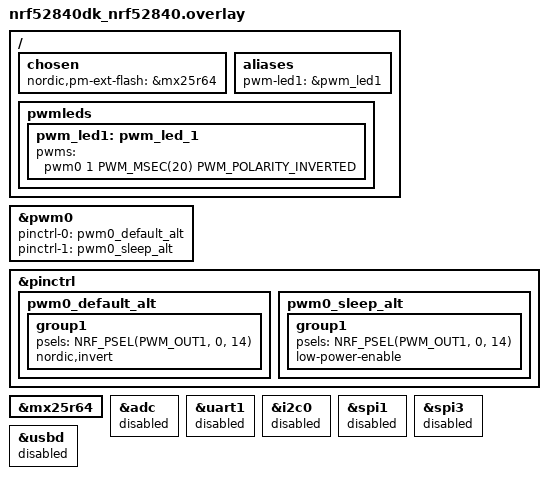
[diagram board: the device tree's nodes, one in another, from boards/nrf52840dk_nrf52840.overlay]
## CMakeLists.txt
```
#
# Copyright (c) 2021 Nordic Semiconductor ASA
#
# SPDX-License-Identifier: LicenseRef-Nordic-5-Clause
#

cmake_minimum_required(VERSION 3.20.0)

find_package(Zephyr HINTS $ENV{ZEPHYR_BASE})

project(matter-light-bulb)

# Enable GNU STD support.
include(${ZEPHYR_CONNECTEDHOMEIP_MODULE_DIR}/config/nrfconnect/app/enable-gnu-std.cmake)

# NORDIC SDK APP START

# Include all source files that are located in the Matter common directory.
include(${ZEPHYR_NRF_MODULE_DIR}/samples/matter/common/cmake/source_common.cmake)

# Include Data Model utils
include(${ZEPHYR_NRF_MODULE_DIR}/samples/matter/common/cmake/data_model.cmake)

include(${ZEPHYR_NRF_MODULE_DIR}/samples/matter/common/cmake/zap_helpers.cmake)
ncs_get_zap_parent_dir(ZAP_PARENT_DIR)

target_include_directories(app PRIVATE
  src
  ${ZAP_PARENT_DIR}
)

target_sources(app PRIVATE
  src/app_task.cpp
  src/main.cpp
  src/zcl_callbacks.cpp
  ${CHIP_ROOT}/src/app/persistence/DeferredAttributePersistenceProvider.cpp
)

ncs_configure_data_model()
# NORDIC SDK APP END
```

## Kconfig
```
#
# Copyright (c) 2022 Nordic Semiconductor
#
# SPDX-License-Identifier: LicenseRef-Nordic-5-Clause
#
mainmenu "Matter nRF Connect Light Bulb Example Application"

# Sample configuration used for Thread networking
if OPENTHREAD

choice OPENTHREAD_NORDIC_LIBRARY_CONFIGURATION
	default OPENTHREAD_NORDIC_LIBRARY_FTD
endchoice

choice OPENTHREAD_DEVICE_TYPE
	default OPENTHREAD_FTD
endchoice

endif # OPENTHREAD

config CHIP_WIFI
	default y if SHIELD_NRF7002EB2

source "$(ZEPHYR_CONNECTEDHOMEIP_MODULE_DIR)/config/nrfconnect/chip-module/Kconfig.features"
source "$(ZEPHYR_CONNECTEDHOMEIP_MODULE_DIR)/config/nrfconnect/chip-module/Kconfig.defaults"
source "$(ZEPHYR_NRF_MODULE_DIR)/samples/matter/common/src/Kconfig"
source "Kconfig.zephyr"
```

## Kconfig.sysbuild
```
#
# Copyright (c) 2023 Nordic Semiconductor ASA
#
# SPDX-License-Identifier: LicenseRef-Nordic-5-Clause
#

#### Radio core selection
config NRF_DEFAULT_IPC_RADIO
	default y

# Enable IEEE802.15.4 serialization to network core
# This config automatically pulls in the `overlay-802154.conf` in the ipc_radio image
config NETCORE_IPC_RADIO_IEEE802154
	default y if SOC_SERIES_NRF53 && !WIFI_NRF70

# Enable Bluetooth serialization to network core
# This config automatically pulls in the `overlay-bt_hci_ipc.conf` in the ipc_radio image
config NETCORE_IPC_RADIO_BT_HCI_IPC
	default y if SOC_SERIES_NRF53

#### Bootloader
choice BOOTLOADER
	default BOOTLOADER_MCUBOOT if !BOARD_NRF21540DK
endchoice

# The nRF54LC10 DK keeps MCUboot but uses a single application slot:
# it has no external flash and its RRAM cannot hold two Matter-sized slots.
# DFU can be added by introducing external flash.
config MATTER_OTA
	default n if BOARD_NRF54LC10DK

if BOOTLOADER_MCUBOOT

#### DFU multi-image support
config DFU_MULTI_IMAGE_PACKAGE_BUILD
	default y

config DFU_MULTI_IMAGE_PACKAGE_APP
	default y

#### DFU network core configuration
if SOC_SERIES_NRF53

choice MCUBOOT_MODE
	default MCUBOOT_MODE_OVERWRITE_ONLY
endchoice

choice BOOT_SIGNATURE_TYPE
	default BOOT_SIGNATURE_TYPE_RSA
endchoice

config SECURE_BOOT_NETCORE
	default y

config NETCORE_APP_UPDATE
	default y

config MCUBOOT_NRF53_MULTI_IMAGE_UPDATE
	default y if NETCORE_APP_UPDATE

config DFU_MULTI_IMAGE_PACKAGE_NET
	default y

endif # SOC_SERIES_NRF53

# Disable Secondary slot for nRF54LC10 DK since it lacks memory to support it.
if BOARD_NRF54LC10DK

choice MCUBOOT_MODE
	default MCUBOOT_MODE_SINGLE_APP
endchoice

endif # BOARD_NRF54LC10DK

endif # BOOTLOADER_MCUBOOT

#### Enable generating factory data
config MATTER_FACTORY_DATA_GENERATE
	default y if !BOARD_NRF21540DK

source "share/sysbuild/Kconfig"
```

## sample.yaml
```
sample:
  description: Matter Light Bulb example
  name: Matter Light Bulb
common:
  tags:
    - sysbuild
    - ci_samples_matter
tests:
  sample.matter.light_bulb.debug:
    sysbuild: true
    build_only: true
    integration_platforms:
      - nrf54lm20dk/nrf54lm20b/cpuapp
    platform_allow:
      - nrf52840dk/nrf52840
      - nrf5340dk/nrf5340/cpuapp
      - nrf54l15dk/nrf54l15/cpuapp
      - nrf54lm20dk/nrf54lm20b/cpuapp
      - nrf54lm20dk/nrf54lm20a/cpuapp
  sample.matter.light_bulb.nrf7002eb2.debug:
    sysbuild: true
    build_only: true
    extra_args:
      - light_bulb_SHIELD=nrf7002eb2
      - SB_CONFIG_WIFI_NRF70=y
    integration_platforms:
      - nrf54lm20dk/nrf54lm20b/cpuapp
      - nrf54lm20dk/nrf54lm20a/cpuapp
    platform_allow:
      - nrf54lm20dk/nrf54lm20b/cpuapp
      - nrf54lm20dk/nrf54lm20a/cpuapp
  sample.matter.light_bulb.release:
    sysbuild: true
    build_only: true
    extra_args:
      - FILE_SUFFIX=release
    integration_platforms:
      - nrf54lm20dk/nrf54lm20b/cpuapp
      - nrf54lm20dk/nrf54lm20a/cpuapp
    platform_allow:
      - nrf52840dk/nrf52840
      - nrf5340dk/nrf5340/cpuapp
      - nrf54l15dk/nrf54l15/cpuapp
      - nrf54lm20dk/nrf54lm20b/cpuapp
      - nrf54lm20dk/nrf54lm20a/cpuapp
  sample.matter.light_bulb.nrf7002eb2.release:
    sysbuild: true
    build_only: true
    extra_args:
      - FILE_SUFFIX=release
      - light_bulb_SHIELD=nrf7002eb2
      - SB_CONFIG_WIFI_NRF70=y
    integration_platforms:
      - nrf54lm20dk/nrf54lm20b/cpuapp
      - nrf54lm20dk/nrf54lm20a/cpuapp
    platform_allow:
      - nrf54lm20dk/nrf54lm20b/cpuapp
      - nrf54lm20dk/nrf54lm20a/cpuapp
  sample.matter.light_bulb.ffs:
    sysbuild: true
    build_only: true
    extra_args:
      - CONFIG_CHIP_COMMISSIONABLE_DEVICE_TYPE=y
      - CONFIG_CHIP_ROTATING_DEVICE_ID=y
      - CONFIG_CHIP_DEVICE_TYPE=257
    integration_platforms:
      - nrf52840dk/nrf52840
      - nrf54l15dk/nrf54l15/cpuapp
      - nrf54lm20dk/nrf54lm20b/cpuapp
      - nrf54lm20dk/nrf54lm20a/cpuapp
    platform_allow:
      - nrf52840dk/nrf52840
      - nrf5340dk/nrf5340/cpuapp
      - nrf54l15dk/nrf54l15/cpuapp
      - nrf54lm20dk/nrf54lm20b/cpuapp
      - nrf54lm20dk/nrf54lm20a/cpuapp
      - nrf54lc10dk/nrf54lc10a/cpuapp
  sample.matter.light_bulb.nrf7002eb2.ffs:
    sysbuild: true
    build_only: true
    extra_args:
      - CONFIG_CHIP_COMMISSIONABLE_DEVICE_TYPE=y
      - CONFIG_CHIP_ROTATING_DEVICE_ID=y
      - CONFIG_CHIP_DEVICE_TYPE=257
      - light_bulb_SHIELD=nrf7002eb2
      - SB_CONFIG_WIFI_NRF70=y
    integration_platforms:
      - nrf54lm20dk/nrf54lm20b/cpuapp
      - nrf54lm20dk/nrf54lm20a/cpuapp
    platform_allow:
      - nrf54lm20dk/nrf54lm20b/cpuapp
      - nrf54lm20dk/nrf54lm20a/cpuapp
  sample.matter.light_bulb.debug.nrf21540ek:
    sysbuild: true
    build_only: true
    extra_args:
      - light_bulb_SHIELD=nrf21540ek
    integration_platforms:
      - nrf52840dk/nrf52840
    platform_allow: nrf52840dk/nrf52840
  sample.matter.light_bulb.debug.nrf21540ek_fwd:
    sysbuild: true
    build_only: true
    extra_args:
      - light_bulb_SHIELD=nrf21540ek
      - ipc_radio_SHIELD=nrf21540ek
    integration_platforms:
      - nrf5340dk/nrf5340/cpuapp
    platform_allow: nrf5340dk/nrf5340/cpuapp
  # Sample to execute load tests
  sample.matter.light_bulb.memory_profiling:
    sysbuild: true
    build_only: true
    extra_args:
      - CONFIG_CHIP_MEMORY_PROFILING=y
      - CONFIG_SHELL_MINIMAL=y
      - CONFIG_CHIP_FACTORY_RESET_TIME_MEASUREMENT=y
    platform_allow:
      - nrf52840dk/nrf52840
      - nrf5340dk/nrf5340/cpuapp
      - nrf54l15dk/nrf54l15/cpuapp
      - nrf54lm20dk/nrf54lm20b/cpuapp
      - nrf54lm20dk/nrf54lm20a/cpuapp
      - nrf54lc10dk/nrf54lc10a/cpuapp
    integration_platforms:
      - nrf54l15dk/nrf54l15/cpuapp
      - nrf54lm20dk/nrf54lm20b/cpuapp
      - nrf54lm20dk/nrf54lm20a/cpuapp
  sample.matter.light_bulb.nrf7002eb2.memory_profiling:
    sysbuild: true
    build_only: true
    extra_args:
      - CONFIG_CHIP_MEMORY_PROFILING=y
      - CONFIG_SHELL_MINIMAL=y
      - CONFIG_CHIP_FACTORY_RESET_TIME_MEASUREMENT=y
      - light_bulb_SHIELD=nrf7002eb2
      - SB_CONFIG_WIFI_NRF70=y
    platform_allow:
      - nrf54lm20dk/nrf54lm20b/cpuapp
      - nrf54lm20dk/nrf54lm20a/cpuapp
    integration_platforms:
      - nrf54lm20dk/nrf54lm20b/cpuapp
      - nrf54lm20dk/nrf54lm20a/cpuapp
  sample.matter.light_bulb.tfm:
    sysbuild: true
    build_only: true
    extra_args:
      - FILE_SUFFIX=tfm
    integration_platforms:
      - nrf54l15dk/nrf54l15/cpuapp/ns
    platform_allow:
      - nrf54l15dk/nrf54l15/cpuapp/ns
```

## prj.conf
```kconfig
#
# Copyright (c) 2022 Nordic Semiconductor ASA
#
# SPDX-License-Identifier: LicenseRef-Nordic-5-Clause
#

# Enable CHIP
CONFIG_CHIP=y
CONFIG_CHIP_PROJECT_CONFIG="src/chip_project_config.h"
CONFIG_CHIP_DEVICE_PRODUCT_NAME="Matter Light Bulb"

# Configure ZAP file name
CONFIG_NCS_SAMPLE_MATTER_ZAP_FILE_PATH="${APPLICATION_CONFIG_DIR}/src/default_zap/light_bulb.zap"

# 32773 == 0x8005 (example lighting-app)
CONFIG_CHIP_DEVICE_PRODUCT_ID=32773
CONFIG_STD_CPP17=y

# Enable Matter pairing automatically on application start.
CONFIG_CHIP_ENABLE_PAIRING_AUTOSTART=y

# Enable Matter extended announcement and increase duration to 1 hour.
CONFIG_CHIP_BLE_EXT_ADVERTISING=y
CONFIG_CHIP_BLE_ADVERTISING_DURATION=60

# Add support for LEDs and buttons on Nordic development kits
CONFIG_DK_LIBRARY=y
CONFIG_PWM=y

# Bluetooth Low Energy configuration
CONFIG_BT_DEVICE_NAME="MatterLight"

# Other settings
CONFIG_THREAD_NAME=y
CONFIG_MPU_STACK_GUARD=y
CONFIG_RESET_ON_FATAL_ERROR=n
CONFIG_CHIP_LIB_SHELL=y
CONFIG_NCS_SAMPLE_MATTER_TEST_SHELL=y

# Reduce application size
CONFIG_USE_SEGGER_RTT=n
```

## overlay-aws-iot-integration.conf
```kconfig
#
# Copyright (c) 2023 Nordic Semiconductor ASA
#
# SPDX-License-Identifier: LicenseRef-Nordic-5-Clause
#

# Enable matter integration layer
CONFIG_AWS_IOT_INTEGRATION=y
CONFIG_AWS_IOT_INTEGRATION_LOG_LEVEL_DBG=y

# AWS IoT library
CONFIG_AWS_IOT=y
CONFIG_AWS_IOT_BROKER_HOST_NAME="xxx.amazonaws.com"
CONFIG_AWS_IOT_CLIENT_ID_STATIC="my-thing"
CONFIG_AWS_IOT_AUTO_DEVICE_SHADOW_REQUEST=n
CONFIG_AWS_IOT_TOPIC_UPDATE_DELTA_SUBSCRIBE=y

# JSON
CONFIG_JSON_LIBRARY=y

# MQTT helper library
CONFIG_MQTT_HELPER_PROVISION_CERTIFICATES=y
CONFIG_MQTT_HELPER_CERTIFICATES_FOLDER="src/aws_iot_integration/certs"
CONFIG_MQTT_HELPER_SEC_TAG=201

# MQTT - Maximum MQTT keepalive timeout specified by AWS IoT Core
CONFIG_MQTT_KEEPALIVE=1200
CONFIG_MQTT_CLEAN_SESSION=y

# MBed TLS
CONFIG_MBEDTLS_HEAP_SIZE=98304
CONFIG_MBEDTLS_RSA_C=y
CONFIG_PSA_WANT_ALG_SHA_384=y
CONFIG_MBEDTLS_SSL_OUT_CONTENT_LEN=1024

# PSA
CONFIG_PSA_WANT_KEY_TYPE_RSA_PUBLIC_KEY=y
CONFIG_PSA_WANT_RSA_KEY_SIZE_2048=y

# Zephyr Networking
CONFIG_NET_CONNECTION_MANAGER=y
CONFIG_NET_DHCPV4=y
CONFIG_NET_IPV4=y
CONFIG_NET_TCP=y
CONFIG_NET_SOCKETS_SOCKOPT_TLS=y
CONFIG_NET_MAX_CONN=8

# Required events at least 9 ZVFS events:
# 5 x WPA supplicant
# 1 x Socket Service
# 1 x DNS resolver
# 1 x Matter Stack
# 1 x MQTT / AWS IoT integration
CONFIG_ZVFS_EVENTFD_MAX=10
CONFIG_ZVFS_POLL_MAX=12
CONFIG_DNS_RESOLVER=y

# Adjust NET configurations to reduce the likelyhood of congestion in the TCP stack when there are
# multiple NET users in the system.
CONFIG_NET_PKT_RX_COUNT=14
CONFIG_NET_PKT_TX_COUNT=14
CONFIG_NET_BUF_RX_COUNT=54
CONFIG_NET_BUF_TX_COUNT=54
CONFIG_NET_TCP_MAX_SEND_WINDOW_SIZE=1024

# Free some memory
CONFIG_SHELL=n
CONFIG_CHIP_LIB_SHELL=n
CONFIG_ASSERT=n
CONFIG_LTO=y
CONFIG_ISR_TABLES_LOCAL_DECLARATION=y
```

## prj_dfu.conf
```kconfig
#
# Copyright (c) 2021 Nordic Semiconductor ASA
#
# SPDX-License-Identifier: LicenseRef-Nordic-5-Clause
#

# Enable CHIP
CONFIG_CHIP=y
CONFIG_CHIP_PROJECT_CONFIG="src/chip_project_config.h"
CONFIG_STD_CPP14=y

# Enable CHIP pairing automatically on application start.
CONFIG_CHIP_ENABLE_PAIRING_AUTOSTART=y

# General networking settings
CONFIG_NETWORKING=y
CONFIG_NET_IPV6_NBR_CACHE=n
CONFIG_NET_IPV6_MLD=n
CONFIG_NET_SOCKETS_POLL_MAX=5

# Enable OpenThread MTD
CONFIG_NET_L2_OPENTHREAD=y

CONFIG_OPENTHREAD_MTD=y
CONFIG_OPENTHREAD_FTD=n
CONFIG_OPENTHREAD_SLAAC=y
CONFIG_OPENTHREAD_MTD_NETDIAG=y
CONFIG_OPENTHREAD_MANUAL_START=y
CONFIG_OPENTHREAD_THREAD_STACK_SIZE=6144
CONFIG_OPENTHREAD_NUM_MESSAGE_BUFFERS=64

CONFIG_OPENTHREAD_PANID=4660
CONFIG_OPENTHREAD_CHANNEL=15
CONFIG_OPENTHREAD_NETWORK_NAME="OpenThread"
CONFIG_OPENTHREAD_XPANID="11:11:11:11:22:22:22:22"

# Enable Bluetooth Low Energy
CONFIG_BT=y
CONFIG_BT_PERIPHERAL=y
CONFIG_BT_PERIPHERAL_PREF_MIN_INT=12
CONFIG_BT_PERIPHERAL_PREF_MAX_INT=12
CONFIG_BT_GAP_AUTO_UPDATE_CONN_PARAMS=y
CONFIG_BT_GATT_DYNAMIC_DB=y
CONFIG_BT_DEVICE_APPEARANCE=0
CONFIG_BT_DEVICE_NAME_DYNAMIC=y
CONFIG_BT_DEVICE_NAME_MAX=15
CONFIG_BT_DEVICE_NAME="MatterLight"
CONFIG_BT_MAX_CONN=1
CONFIG_BT_SMP=y
CONFIG_BT_PRIVACY=y
CONFIG_BT_MAX_PAIRED=0
CONFIG_BT_BONDABLE=n
CONFIG_BT_TINYCRYPT_ECC=n
CONFIG_BT_SMP_OOB_LEGACY_PAIR_ONLY=y

# Use NFC to share commissioning information
CONFIG_CHIP_NFC_COMMISSIONING=y

# Use nrf_security
CONFIG_OPENTHREAD_NRF_SECURITY_CHOICE=y

CONFIG_CC3XX_BACKEND=y
CONFIG_OBERON_BACKEND=y

CONFIG_MBEDTLS_ENABLE_HEAP=y
CONFIG_MBEDTLS_HEAP_SIZE=15360
CONFIG_MBEDTLS_TLS_LIBRARY=y
CONFIG_NRF_SECURITY_ADVANCED=y

CONFIG_MBEDTLS_AES_C=y
CONFIG_MBEDTLS_ECP_C=y
CONFIG_MBEDTLS_ECP_DP_SECP256R1_ENABLED=y
CONFIG_MBEDTLS_CTR_DRBG_C=y
CONFIG_MBEDTLS_CIPHER_MODE_CTR=y
CONFIG_MBEDTLS_ECJPAKE_C=y
CONFIG_MBEDTLS_SHA256_C=y
CONFIG_MBEDTLS_PK_C=y
CONFIG_MBEDTLS_PK_WRITE_C=y
CONFIG_MBEDTLS_X509_CREATE_C=y
CONFIG_MBEDTLS_X509_CSR_WRITE_C=y

# Use SHA256 implementation from Oberon
CONFIG_CHOICE_OBERON_MBEDTLS_SHA256_C=y

# Disable unneeded crypto operations
CONFIG_MBEDTLS_SHA512_C=n
CONFIG_MBEDTLS_CIPHER_MODE_XTS=n
CONFIG_MBEDTLS_CHACHA20_C=n
CONFIG_MBEDTLS_POLY1305_C=n
CONFIG_MBEDTLS_CHACHAPOLY_C=n
CONFIG_MBEDTLS_GCM_C=n
CONFIG_MBEDTLS_RSA_C=n
CONFIG_OBERON_MBEDTLS_AES_C=n

# Add support for LEDs and buttons on Nordic development kits
CONFIG_DK_LIBRARY=y
CONFIG_PWM=y

# Other settings
CONFIG_LOG=y
CONFIG_LOG_MODE_MINIMAL=y
CONFIG_PRINTK_SYNC=y
CONFIG_MAIN_STACK_SIZE=8192
CONFIG_INIT_STACKS=y
CONFIG_HW_STACK_PROTECTION=y
CONFIG_THREAD_NAME=y
CONFIG_SHELL=y

# Enable bootloader and DFU related configs
CONFIG_BOOTLOADER_MCUBOOT=y

# QSPI configuration
CONFIG_NORDIC_QSPI_NOR=y
CONFIG_NORDIC_QSPI_NOR_FLASH_LAYOUT_PAGE_SIZE=4096
CONFIG_NORDIC_QSPI_NOR_STACK_WRITE_BUFFER_SIZE=16

# External flash memory configuration
CONFIG_PM_EXTERNAL_FLASH_SUPPORT_LEGACY=y
CONFIG_PM_EXTERNAL_FLASH=y
CONFIG_PM_EXTERNAL_FLASH_DEV_NAME="MX25R64"
CONFIG_PM_EXTERNAL_FLASH_SIZE=0x800000
CONFIG_PM_EXTERNAL_FLASH_BASE=0

# MCU Manager and SMP configuration
CONFIG_MCUMGR=y
CONFIG_MCUMGR_CMD_IMG_MGMT=y
CONFIG_MCUMGR_CMD_OS_MGMT=y
CONFIG_MCUMGR_SMP_BT=y
CONFIG_MCUMGR_SMP_BT_AUTHEN=n
CONFIG_MCUMGR_BUF_COUNT=6

# Increase BT MTU and RX buffer for big size DFU messages
CONFIG_BT_L2CAP_TX_MTU=260
CONFIG_BT_BUF_ACL_RX_SIZE=264

# Increase system workqueue size, as SMP is processed within it
CONFIG_SYSTEM_WORKQUEUE_STACK_SIZE=2800
```

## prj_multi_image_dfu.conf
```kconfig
#
# Copyright (c) 2021 Nordic Semiconductor ASA
#
# SPDX-License-Identifier: LicenseRef-Nordic-5-Clause
#

# Enable CHIP
CONFIG_CHIP=y
CONFIG_CHIP_PROJECT_CONFIG="src/chip_project_config.h"
CONFIG_STD_CPP14=y

# Enable CHIP pairing automatically on application start.
CONFIG_CHIP_ENABLE_PAIRING_AUTOSTART=y

# General networking settings
CONFIG_NETWORKING=y
CONFIG_NET_IPV6_NBR_CACHE=n
CONFIG_NET_IPV6_MLD=n
CONFIG_NET_SOCKETS_POLL_MAX=5

# Enable OpenThread MTD
CONFIG_NET_L2_OPENTHREAD=y

CONFIG_OPENTHREAD_MTD=y
CONFIG_OPENTHREAD_FTD=n
CONFIG_OPENTHREAD_SLAAC=y
CONFIG_OPENTHREAD_MTD_NETDIAG=y
CONFIG_OPENTHREAD_MANUAL_START=y
CONFIG_OPENTHREAD_THREAD_STACK_SIZE=6144
CONFIG_OPENTHREAD_NUM_MESSAGE_BUFFERS=64

CONFIG_OPENTHREAD_PANID=4660
CONFIG_OPENTHREAD_CHANNEL=15
CONFIG_OPENTHREAD_NETWORK_NAME="OpenThread"
CONFIG_OPENTHREAD_XPANID="11:11:11:11:22:22:22:22"

# Enable Thread 1.2 features
CONFIG_OPENTHREAD_THREAD_VERSION_1_2=y
CONFIG_OPENTHREAD_DUA=y
CONFIG_OPENTHREAD_MLR=y

# Enable Bluetooth Low Energy
CONFIG_BT=y
CONFIG_BT_PERIPHERAL=y
CONFIG_BT_PERIPHERAL_PREF_MIN_INT=12
CONFIG_BT_PERIPHERAL_PREF_MAX_INT=12
CONFIG_BT_GAP_AUTO_UPDATE_CONN_PARAMS=y
CONFIG_BT_GATT_DYNAMIC_DB=y
CONFIG_BT_DEVICE_APPEARANCE=0
CONFIG_BT_DEVICE_NAME_DYNAMIC=y
CONFIG_BT_DEVICE_NAME_MAX=15
CONFIG_BT_DEVICE_NAME="MatterLight"
CONFIG_BT_MAX_CONN=1

# Use NFC to share commissioning information
CONFIG_CHIP_NFC_COMMISSIONING=y

# Use nrf_security
CONFIG_OPENTHREAD_NRF_SECURITY_CHOICE=y

CONFIG_CC3XX_BACKEND=n
CONFIG_OBERON_BACKEND=y

CONFIG_MBEDTLS_ENABLE_HEAP=y
CONFIG_MBEDTLS_HEAP_SIZE=15360
CONFIG_MBEDTLS_TLS_LIBRARY=y
CONFIG_NRF_SECURITY_ADVANCED=y

CONFIG_MBEDTLS_AES_C=y
CONFIG_MBEDTLS_ECP_C=y
CONFIG_MBEDTLS_ECP_DP_SECP256R1_ENABLED=y
CONFIG_MBEDTLS_CTR_DRBG_C=y
CONFIG_MBEDTLS_CIPHER_MODE_CTR=y
CONFIG_MBEDTLS_ECJPAKE_C=y
CONFIG_MBEDTLS_SHA256_C=y
CONFIG_MBEDTLS_PK_C=y
CONFIG_MBEDTLS_PK_WRITE_C=y
CONFIG_MBEDTLS_X509_CREATE_C=y
CONFIG_MBEDTLS_X509_CSR_WRITE_C=y
# Disable unneeded crypto operations
CONFIG_MBEDTLS_SHA384_C=n
CONFIG_MBEDTLS_SHA512_C=n
CONFIG_MBEDTLS_CIPHER_MODE_XTS=n
CONFIG_MBEDTLS_CHACHA20_C=n
CONFIG_MBEDTLS_POLY1305_C=n
CONFIG_MBEDTLS_CHACHAPOLY_C=n
CONFIG_MBEDTLS_GCM_C=n
CONFIG_MBEDTLS_RSA_C=n

# Add support for LEDs and buttons on Nordic development kits
CONFIG_DK_LIBRARY=y
CONFIG_PWM=y

# Other settings
CONFIG_LOG=y
CONFIG_LOG_MODE_MINIMAL=y
CONFIG_MATTER_LOG_LEVEL_DBG=y
CONFIG_PRINTK_SYNC=y
CONFIG_MAIN_STACK_SIZE=8192
CONFIG_INIT_STACKS=y
CONFIG_HW_STACK_PROTECTION=y
CONFIG_HWINFO=y
CONFIG_THREAD_NAME=y
CONFIG_SHELL=y
CONFIG_ASSERT=y

# Enable bootloader and DFU related configs
CONFIG_BOOTLOADER_MCUBOOT=y
CONFIG_UPDATEABLE_IMAGE_NUMBER=2

# QSPI configuration
CONFIG_NORDIC_QSPI_NOR=y
CONFIG_NORDIC_QSPI_NOR_FLASH_LAYOUT_PAGE_SIZE=4096
CONFIG_NORDIC_QSPI_NOR_STACK_WRITE_BUFFER_SIZE=16

# MCU Manager and SMP configuration
CONFIG_MCUMGR=y
CONFIG_MCUMGR_CMD_IMG_MGMT=y
CONFIG_MCUMGR_CMD_OS_MGMT=y
CONFIG_MCUMGR_SMP_BT=y
CONFIG_MCUMGR_SMP_BT_AUTHEN=n
CONFIG_MCUMGR_BUF_COUNT=6

# Increase BT MTU and RX buffer for big size DFU messages
CONFIG_BT_L2CAP_TX_MTU=498
CONFIG_BT_BUF_ACL_TX_SIZE=251
CONFIG_BT_BUF_ACL_RX_SIZE=502

# Increase max number of pending GATT notification callbacks
CONFIG_BT_CONN_TX_MAX=6

# Increase system workqueue size, as SMP is processed within it
CONFIG_SYSTEM_WORKQUEUE_STACK_SIZE=2800

# FLASH nop device is enabled to prevent bus faults when mcumgr tries to access
# simulated partition with network core image data.
CONFIG_FLASH_NOP_DEVICE=y

# Enable custom SMP request to erase settings partition.
CONFIG_MCUMGR_GRP_ZEPHYR_BASIC=y
CONFIG_MCUMGR_GRP_BASIC_CMD_STORAGE_ERASE=y
```

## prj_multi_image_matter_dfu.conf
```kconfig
#
# Copyright (c) 2022 Nordic Semiconductor ASA
#
# SPDX-License-Identifier: LicenseRef-Nordic-5-Clause
#

# Enable CHIP
CONFIG_CHIP=y
CONFIG_CHIP_PROJECT_CONFIG="src/chip_project_config.h"
CONFIG_STD_CPP14=y

# Enable CHIP pairing automatically on application start.
CONFIG_CHIP_ENABLE_PAIRING_AUTOSTART=y

# General networking settings
CONFIG_NETWORKING=y
CONFIG_NET_IPV6_NBR_CACHE=n
CONFIG_NET_IPV6_MLD=n
CONFIG_NET_SOCKETS_POLL_MAX=5

# Enable OpenThread MTD
CONFIG_NET_L2_OPENTHREAD=y

CONFIG_OPENTHREAD_MTD=y
CONFIG_OPENTHREAD_FTD=n
CONFIG_OPENTHREAD_SLAAC=y
CONFIG_OPENTHREAD_MTD_NETDIAG=y
CONFIG_OPENTHREAD_MANUAL_START=y
CONFIG_OPENTHREAD_NUM_MESSAGE_BUFFERS=64

CONFIG_OPENTHREAD_PANID=4660
CONFIG_OPENTHREAD_CHANNEL=15
CONFIG_OPENTHREAD_NETWORK_NAME="OpenThread"
CONFIG_OPENTHREAD_XPANID="11:11:11:11:22:22:22:22"

# Enable Thread 1.2 features
CONFIG_OPENTHREAD_THREAD_VERSION_1_2=y
CONFIG_OPENTHREAD_DUA=y
CONFIG_OPENTHREAD_MLR=y

# Enable Bluetooth Low Energy
CONFIG_BT=y
CONFIG_BT_PERIPHERAL=y
CONFIG_BT_PERIPHERAL_PREF_MIN_INT=36
CONFIG_BT_PERIPHERAL_PREF_MAX_INT=36
CONFIG_BT_GAP_AUTO_UPDATE_CONN_PARAMS=y
CONFIG_BT_GATT_DYNAMIC_DB=y
CONFIG_BT_DEVICE_APPEARANCE=0
CONFIG_BT_DEVICE_NAME_DYNAMIC=y
CONFIG_BT_DEVICE_NAME_MAX=15
CONFIG_BT_DEVICE_NAME="MatterLight"
CONFIG_BT_MAX_CONN=1
CONFIG_BT_L2CAP_TX_MTU=247
CONFIG_BT_BUF_ACL_RX_SIZE=251
CONFIG_BT_BUF_ACL_TX_SIZE=251
CONFIG_BT_RX_STACK_SIZE=1120

# Use NFC to share commissioning information
CONFIG_CHIP_NFC_COMMISSIONING=y

# Use nrf_security
CONFIG_OPENTHREAD_NRF_SECURITY_CHOICE=y

CONFIG_CC3XX_BACKEND=n
CONFIG_OBERON_BACKEND=y

CONFIG_MBEDTLS_ENABLE_HEAP=y
CONFIG_MBEDTLS_HEAP_SIZE=15360
CONFIG_MBEDTLS_TLS_LIBRARY=y
CONFIG_NRF_SECURITY_ADVANCED=y

CONFIG_MBEDTLS_AES_C=y
CONFIG_MBEDTLS_ECP_C=y
CONFIG_MBEDTLS_ECP_DP_SECP256R1_ENABLED=y
CONFIG_MBEDTLS_CTR_DRBG_C=y
CONFIG_MBEDTLS_CIPHER_MODE_CTR=y
CONFIG_MBEDTLS_ECJPAKE_C=y
CONFIG_MBEDTLS_SHA256_C=y
CONFIG_MBEDTLS_PK_C=y
CONFIG_MBEDTLS_PK_WRITE_C=y
CONFIG_MBEDTLS_X509_CREATE_C=y
CONFIG_MBEDTLS_X509_CSR_WRITE_C=y

# Disable unneeded crypto operations
CONFIG_MBEDTLS_SHA384_C=n
CONFIG_MBEDTLS_SHA512_C=n
CONFIG_MBEDTLS_CIPHER_MODE_XTS=n
CONFIG_MBEDTLS_CHACHA20_C=n
CONFIG_MBEDTLS_POLY1305_C=n
CONFIG_MBEDTLS_CHACHAPOLY_C=n
CONFIG_MBEDTLS_GCM_C=n
CONFIG_MBEDTLS_RSA_C=n

# Add support for LEDs and buttons on Nordic development kits
CONFIG_DK_LIBRARY=y
CONFIG_PWM=y

# Other settings
CONFIG_LOG=y
CONFIG_LOG_MODE_MINIMAL=y
CONFIG_MATTER_LOG_LEVEL_DBG=y
CONFIG_PRINTK_SYNC=y
CONFIG_MAIN_STACK_SIZE=8192
CONFIG_INIT_STACKS=y
CONFIG_HW_STACK_PROTECTION=y
CONFIG_FPU=y
CONFIG_HWINFO=y
CONFIG_THREAD_NAME=y
CONFIG_SHELL=y
CONFIG_ASSERT=y

# Enable bootloader and DFU related configs
CONFIG_BOOTLOADER_MCUBOOT=y
CONFIG_UPDATEABLE_IMAGE_NUMBER=2

# QSPI configuration
CONFIG_NORDIC_QSPI_NOR=y
CONFIG_NORDIC_QSPI_NOR_FLASH_LAYOUT_PAGE_SIZE=4096
CONFIG_NORDIC_QSPI_NOR_STACK_WRITE_BUFFER_SIZE=16

# FLASH nop device is needed to access network core image data.
CONFIG_FLASH_NOP_DEVICE=y

# Enable Matter OTA
CONFIG_CHIP_OTA_REQUESTOR=y
CONFIG_IMG_MANAGER=y
```

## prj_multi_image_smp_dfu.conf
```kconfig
#
# Copyright (c) 2021 Nordic Semiconductor ASA
#
# SPDX-License-Identifier: LicenseRef-Nordic-5-Clause
#

# Enable CHIP
CONFIG_CHIP=y
CONFIG_CHIP_PROJECT_CONFIG="src/chip_project_config.h"
CONFIG_STD_CPP14=y

# Enable CHIP pairing automatically on application start.
CONFIG_CHIP_ENABLE_PAIRING_AUTOSTART=y

# General networking settings
CONFIG_NETWORKING=y
CONFIG_NET_IPV6_NBR_CACHE=n
CONFIG_NET_IPV6_MLD=n
CONFIG_NET_SOCKETS_POLL_MAX=5

# Enable OpenThread MTD
CONFIG_NET_L2_OPENTHREAD=y

CONFIG_OPENTHREAD_MTD=y
CONFIG_OPENTHREAD_FTD=n
CONFIG_OPENTHREAD_SLAAC=y
CONFIG_OPENTHREAD_MTD_NETDIAG=y
CONFIG_OPENTHREAD_MANUAL_START=y
CONFIG_OPENTHREAD_NUM_MESSAGE_BUFFERS=64

CONFIG_OPENTHREAD_PANID=4660
CONFIG_OPENTHREAD_CHANNEL=15
CONFIG_OPENTHREAD_NETWORK_NAME="OpenThread"
CONFIG_OPENTHREAD_XPANID="11:11:11:11:22:22:22:22"

# Enable Thread 1.2 features
CONFIG_OPENTHREAD_THREAD_VERSION_1_2=y
CONFIG_OPENTHREAD_DUA=y
CONFIG_OPENTHREAD_MLR=y

# Enable Bluetooth Low Energy
CONFIG_BT=y
CONFIG_BT_PERIPHERAL=y
CONFIG_BT_PERIPHERAL_PREF_MIN_INT=36
CONFIG_BT_PERIPHERAL_PREF_MAX_INT=36
CONFIG_BT_GAP_AUTO_UPDATE_CONN_PARAMS=y
CONFIG_BT_GATT_DYNAMIC_DB=y
CONFIG_BT_DEVICE_APPEARANCE=0
CONFIG_BT_DEVICE_NAME_DYNAMIC=y
CONFIG_BT_DEVICE_NAME_MAX=15
CONFIG_BT_DEVICE_NAME="MatterLight"
CONFIG_BT_MAX_CONN=1
CONFIG_BT_RX_STACK_SIZE=1120

# Use NFC to share commissioning information
CONFIG_CHIP_NFC_COMMISSIONING=y

# Use nrf_security
CONFIG_OPENTHREAD_NRF_SECURITY_CHOICE=y

CONFIG_CC3XX_BACKEND=n
CONFIG_OBERON_BACKEND=y

CONFIG_MBEDTLS_ENABLE_HEAP=y
CONFIG_MBEDTLS_HEAP_SIZE=15360
CONFIG_MBEDTLS_TLS_LIBRARY=y
CONFIG_NRF_SECURITY_ADVANCED=y

CONFIG_MBEDTLS_AES_C=y
CONFIG_MBEDTLS_ECP_C=y
CONFIG_MBEDTLS_ECP_DP_SECP256R1_ENABLED=y
CONFIG_MBEDTLS_CTR_DRBG_C=y
CONFIG_MBEDTLS_CIPHER_MODE_CTR=y
CONFIG_MBEDTLS_ECJPAKE_C=y
CONFIG_MBEDTLS_SHA256_C=y
CONFIG_MBEDTLS_PK_C=y
CONFIG_MBEDTLS_PK_WRITE_C=y
CONFIG_MBEDTLS_X509_CREATE_C=y
CONFIG_MBEDTLS_X509_CSR_WRITE_C=y

# Disable unneeded crypto operations
CONFIG_MBEDTLS_SHA384_C=n
CONFIG_MBEDTLS_SHA512_C=n
CONFIG_MBEDTLS_CIPHER_MODE_XTS=n
CONFIG_MBEDTLS_CHACHA20_C=n
CONFIG_MBEDTLS_POLY1305_C=n
CONFIG_MBEDTLS_CHACHAPOLY_C=n
CONFIG_MBEDTLS_GCM_C=n
CONFIG_MBEDTLS_RSA_C=n

# Add support for LEDs and buttons on Nordic development kits
CONFIG_DK_LIBRARY=y
CONFIG_PWM=y

# Other settings
CONFIG_LOG=y
CONFIG_LOG_MODE_MINIMAL=y
CONFIG_MATTER_LOG_LEVEL_DBG=y
CONFIG_PRINTK_SYNC=y
CONFIG_MAIN_STACK_SIZE=8192
CONFIG_INIT_STACKS=y
CONFIG_HW_STACK_PROTECTION=y
CONFIG_FPU=y
CONFIG_HWINFO=y
CONFIG_THREAD_NAME=y
CONFIG_SHELL=y
CONFIG_ASSERT=y

# Enable bootloader and DFU related configs
CONFIG_BOOTLOADER_MCUBOOT=y
CONFIG_UPDATEABLE_IMAGE_NUMBER=2

# QSPI configuration
CONFIG_NORDIC_QSPI_NOR=y
CONFIG_NORDIC_QSPI_NOR_FLASH_LAYOUT_PAGE_SIZE=4096
CONFIG_NORDIC_QSPI_NOR_STACK_WRITE_BUFFER_SIZE=16

# MCU Manager and SMP configuration
CONFIG_MCUMGR=y
CONFIG_MCUMGR_CMD_IMG_MGMT=y
CONFIG_MCUMGR_CMD_OS_MGMT=y
CONFIG_MCUMGR_SMP_BT=y
CONFIG_MCUMGR_SMP_BT_AUTHEN=n
CONFIG_MCUMGR_BUF_COUNT=6

# Increase BT MTU and RX buffer for big size DFU messages
CONFIG_BT_L2CAP_TX_MTU=498
CONFIG_BT_BUF_ACL_TX_SIZE=251
CONFIG_BT_BUF_ACL_RX_SIZE=502

# Increase max number of pending GATT notification callbacks
CONFIG_BT_CONN_TX_MAX=6

# Increase system workqueue size, as SMP is processed within it
CONFIG_SYSTEM_WORKQUEUE_STACK_SIZE=2800

# FLASH nop device is enabled to prevent bus faults when mcumgr tries to access
# simulated partition with network core image data.
CONFIG_FLASH_NOP_DEVICE=y

# Enable custom SMP request to erase settings partition.
CONFIG_MCUMGR_GRP_ZEPHYR_BASIC=y
CONFIG_MCUMGR_GRP_BASIC_CMD_STORAGE_ERASE=y

# Enable Matter OTA
CONFIG_CHIP_OTA_REQUESTOR=y
```

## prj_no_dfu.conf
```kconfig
#
# Copyright (c) 2022 Nordic Semiconductor ASA
#
# SPDX-License-Identifier: LicenseRef-Nordic-5-Clause
#

# Enable CHIP
CONFIG_CHIP=y
CONFIG_CHIP_PROJECT_CONFIG="src/chip_project_config.h"
# 32773 == 0x8005 (example lighting-app)
CONFIG_CHIP_DEVICE_PRODUCT_ID=32773
CONFIG_STD_CPP17=y

# Enable CHIP pairing automatically on application start.
CONFIG_CHIP_ENABLE_PAIRING_AUTOSTART=y

# Add support for LEDs and buttons on Nordic development kits
CONFIG_DK_LIBRARY=y
CONFIG_PWM=y

# Bluetooth Low Energy configuration
CONFIG_BT_DEVICE_NAME="MatterLight"

# Other settings
CONFIG_THREAD_NAME=y
CONFIG_MPU_STACK_GUARD=y
CONFIG_RESET_ON_FATAL_ERROR=n
CONFIG_CHIP_LIB_SHELL=y

# Disable Matter OTA DFU
CONFIG_CHIP_OTA_REQUESTOR=n

# Disable QSPI NOR
CONFIG_CHIP_QSPI_NOR=n

# Reduce application size
CONFIG_USE_SEGGER_RTT=n
```

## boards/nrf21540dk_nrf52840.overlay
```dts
/*
 * Copyright (c) 2021-2022 Nordic Semiconductor ASA
 *
 * SPDX-License-Identifier: LicenseRef-Nordic-5-Clause
 */

#include <samples/matter/nrf52840_partitions.dtsi>

/ {
	/*
	 * By default, PWM module is only configured for led0 (LED1 on the board).
	 * The light bulb app, however, uses LED2 to show the state of the lighting,
	 * including its brightness level.
	 */
	aliases {
		pwm-led1 = &pwm_led1;
	};

	pwmleds {
		pwm_led1: pwm_led_1 {
			pwms = <&pwm0 1 PWM_MSEC(20) PWM_POLARITY_INVERTED>;
		};
	};
};

&pwm0 {
	pinctrl-0 = <&pwm0_default_alt>;
	pinctrl-1 = <&pwm0_sleep_alt>;
	pinctrl-names = "default", "sleep";
};

&pinctrl {
	pwm0_default_alt: pwm0_default_alt {
		group1 {
			psels = <NRF_PSEL(PWM_OUT1, 0, 14)>;
			nordic,invert;
		};
	};

	pwm0_sleep_alt: pwm0_sleep_alt {
		group1 {
			psels = <NRF_PSEL(PWM_OUT1, 0, 14)>;
			low-power-enable;
		};
	};
};

/* Disable unused peripherals to reduce power consumption */
&adc {
	status = "disabled";
};

&uart1 {
	status = "disabled";
};

&i2c0 {
	status = "disabled";
};

&spi1 {
	status = "disabled";
};

&spi3 {
	status = "disabled";
};

&usbd {
	status = "disabled";
};
```

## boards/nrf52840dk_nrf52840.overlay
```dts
/*
 * Copyright (c) 2021-2022 Nordic Semiconductor ASA
 *
 * SPDX-License-Identifier: LicenseRef-Nordic-5-Clause
 */

#include <samples/matter/nrf52840_partitions.dtsi>

/ {
	chosen {
		nordic,pm-ext-flash = &mx25r64;
	};

	/*
	 * By default, PWM module is only configured for led0 (LED1 on the board).
	 * The light bulb app, however, uses LED2 to show the state of the lighting,
	 * including its brightness level.
	 */
	aliases {
		pwm-led1 = &pwm_led1;
	};

	pwmleds {
		pwm_led1: pwm_led_1 {
			pwms = <&pwm0 1 PWM_MSEC(20) PWM_POLARITY_INVERTED>;
		};
	};
};

&pwm0 {
	pinctrl-0 = <&pwm0_default_alt>;
	pinctrl-1 = <&pwm0_sleep_alt>;
	pinctrl-names = "default", "sleep";
};

&pinctrl {
	pwm0_default_alt: pwm0_default_alt {
		group1 {
			psels = <NRF_PSEL(PWM_OUT1, 0, 14)>;
			nordic,invert;
		};
	};

	pwm0_sleep_alt: pwm0_sleep_alt {
		group1 {
			psels = <NRF_PSEL(PWM_OUT1, 0, 14)>;
			low-power-enable;
		};
	};
};

&mx25r64 {
	status = "okay";
};

/* Disable unused peripherals to reduce power consumption */
&adc {
	status = "disabled";
};

&uart1 {
	status = "disabled";
};

&i2c0 {
	status = "disabled";
};

&spi1 {
	status = "disabled";
};

&spi3 {
	status = "disabled";
};

&usbd {
	status = "disabled";
};
```

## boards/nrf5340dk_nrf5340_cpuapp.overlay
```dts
/*
 * Copyright (c) 2021-2022 Nordic Semiconductor ASA
 *
 * SPDX-License-Identifier: LicenseRef-Nordic-5-Clause
 */

#include <samples/matter/nrf5340_cpuapp_partitions.dtsi>
#include <zephyr/dt-bindings/ipc_service/static_vrings.h>

/ {
	chosen {
		nordic,pm-ext-flash = &mx25r64;
	};

	/*
	 * By default, PWM module is only configured for led0 (LED1 on the board).
	 * The light bulb app, however, uses LED2 to show the state of the lighting,
	 * including its brightness level.
	 */
	aliases {
		pwm-led1 = &pwm_led1;
	};

	pwmleds {
		compatible = "pwm-leds";

		pwm_led1: pwm_led_1 {
			pwms = <&pwm0 1 PWM_MSEC(20) PWM_POLARITY_INVERTED>;
		};
	};
};

/* Set IPC thread priority to the highest value to not collide with other threads. */
&ipc0 {
	zephyr,priority = <0 PRIO_COOP>;
};

&pwm0 {
	pinctrl-0 = <&pwm0_default_alt>;
	pinctrl-1 = <&pwm0_sleep_alt>;
	pinctrl-names = "default", "sleep";
};

&pinctrl {
	pwm0_default_alt: pwm0_default_alt {
		group1 {
			psels = <NRF_PSEL(PWM_OUT1, 0, 29)>;
			nordic,invert;
		};
	};

	pwm0_sleep_alt: pwm0_sleep_alt {
		group1 {
			psels = <NRF_PSEL(PWM_OUT1, 0, 29)>;
			low-power-enable;
		};
	};
};

&mx25r64 {
	status = "okay";
};

/* Disable unused peripherals to reduce power consumption */
&adc {
	status = "disabled";
};

&i2c1 {
	status = "disabled";
};

&spi2 {
	status = "disabled";
};

&usbd {
	status = "disabled";
};
```

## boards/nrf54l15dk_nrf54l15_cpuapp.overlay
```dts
/*
 * Copyright (c) 2024 Nordic Semiconductor ASA
 *
 * SPDX-License-Identifier: LicenseRef-Nordic-5-Clause
 */

#include <samples/matter/nrf54l15_cpuapp_partitions.dtsi>

/ {
	chosen {
		nordic,pm-ext-flash = &mx25r64;
	};

	aliases {
		/* Configure PWM module for led1 (LED2 on the board) */
		pwm-led1 = &pwm_led1;

		/* Use watchdog wdt31 as the application watchdog */
		watchdog0 = &wdt31;
	};

	pwmleds {
		compatible = "pwm-leds";

		pwm_led1: pwm_led_1 {
			pwms = <&pwm20 1 PWM_MSEC(20) PWM_POLARITY_NORMAL>;
		};
	};
};

&mx25r64 {
	status = "okay";
};

&pwm20 {
	status = "okay";
	pinctrl-0 = <&pwm_default>;
	pinctrl-1 = <&pwm_sleep>;
	pinctrl-names = "default", "sleep";
};

&pinctrl {
	pwm_default: pwm_default {
		group1 {
			psels = <NRF_PSEL(PWM_OUT1, 1, 10)>;
		};
	};

	pwm_sleep: pwm_sleep {
		group1 {
			psels = <NRF_PSEL(PWM_OUT1, 1, 10)>;
			low-power-enable;
		};
	};
};

&wdt31 {
	status = "okay";
};
```

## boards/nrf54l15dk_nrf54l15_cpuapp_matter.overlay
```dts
/*
 * Copyright (c) 2024 Nordic Semiconductor ASA
 *
 * SPDX-License-Identifier: LicenseRef-Nordic-5-Clause
 */

/ {
	aliases {
		/* Configure PWM module for led1 (LED2 on the board) */
		pwm-led1 = &pwm_led1;

		/* Use watchdog wdt31 as the application watchdog */
		watchdog0 = &wdt31;
	};

	pwmleds {
		compatible = "pwm-leds";
		pwm_led1: pwm_led_1 {
			pwms = <&pwm20 1 PWM_MSEC(20) PWM_POLARITY_NORMAL>;
		};
	};
};

/* restore full RRAM and SRAM space - by default some parts are dedicated to FLRP */
&cpuapp_rram {
	reg = <0x0 DT_SIZE_K(1524)>;
};

&cpuapp_sram {
	reg = <0x20000000 DT_SIZE_K(256)>;
	ranges = <0x0 0x20000000 0x40000>;
};

/* TODO: re-enable HWFC once it's fixed */
&uart20 {
	/delete-property/ hw-flow-control;
};

&mx25r64 {
	status = "okay";
};

&pwm20 {
	status = "okay";
	pinctrl-0 = <&pwm_default>;
	pinctrl-1 = <&pwm_sleep>;
	pinctrl-names = "default", "sleep";
};

&pinctrl {
	pwm_default: pwm_default {
		group1 {
			psels = <NRF_PSEL(PWM_OUT1, 1, 10)>;
		};
	};
	pwm_sleep: pwm_sleep {
		group1 {
			psels = <NRF_PSEL(PWM_OUT1, 1, 10)>;
			low-power-enable;
		};
	};
};

&wdt31 {
	status = "okay";
};
```

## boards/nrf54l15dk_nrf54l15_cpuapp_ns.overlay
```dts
/*
 * Copyright (c) 2024 Nordic Semiconductor ASA
 *
 * SPDX-License-Identifier: LicenseRef-Nordic-5-Clause
 */

#include <samples/matter/nrf54l15_cpuapp_ns_partitions.dtsi>

/ {
	aliases {
		/* Configure PWM module for led1 (LED2 on the board) */
		pwm-led1 = &pwm_led1;

		/* Use watchdog wdt31 as the application watchdog */
		watchdog0 = &wdt31;
	};

	chosen {
		nordic,pm-ext-flash = &mx25r64;
	};

	pwmleds {
		compatible = "pwm-leds";

		pwm_led1: pwm_led_1 {
			pwms = <&pwm20 1 PWM_MSEC(20) PWM_POLARITY_NORMAL>;
		};
	};
};

&mx25r64 {
	status = "okay";
};

&pwm20 {
	status = "okay";
	pinctrl-0 = <&pwm_default>;
	pinctrl-1 = <&pwm_sleep>;
	pinctrl-names = "default", "sleep";
};

&pinctrl {
	pwm_default: pwm_default {
		group1 {
			psels = <NRF_PSEL(PWM_OUT1, 1, 10)>;
		};
	};

	pwm_sleep: pwm_sleep {
		group1 {
			psels = <NRF_PSEL(PWM_OUT1, 1, 10)>;
			low-power-enable;
		};
	};
};

&wdt31 {
	status = "okay";
};

/* Change IRQ ids to handle button interrupts.
 * The default values for nRF54L15 are 219 and 269,
 * but with TF-M they are reserved for the secure domain
 * (218 and 268 are reserved for the non-secure domain).
 */
&gpiote20 {
	interrupts = <218 NRF_DEFAULT_IRQ_PRIORITY>;
};

&gpiote30 {
	interrupts = <268 NRF_DEFAULT_IRQ_PRIORITY>;
};
```

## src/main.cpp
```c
/*
 * Copyright (c) 2021 Nordic Semiconductor ASA
 *
 * SPDX-License-Identifier: LicenseRef-Nordic-5-Clause
 */

#include "app_task.h"

#include <zephyr/logging/log.h>

LOG_MODULE_REGISTER(app, CONFIG_MATTER_LOG_LEVEL);

int main()
{
	CHIP_ERROR err = GetAppTask().StartApp();

	LOG_ERR("Exited with code %" CHIP_ERROR_FORMAT, err.Format());
	return err == CHIP_NO_ERROR ? EXIT_SUCCESS : EXIT_FAILURE;
}
```

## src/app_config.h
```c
/*
 * Copyright (c) 2022 Nordic Semiconductor ASA
 *
 * SPDX-License-Identifier: LicenseRef-Nordic-5-Clause
 */

#pragma once

/* ---- Light Bulb App Config ---- */

#include "board_util.h"

#define FUNCTION_BUTTON DK_BTN1
#define FUNCTION_BUTTON_MASK DK_BTN1_MSK

#if NUMBER_OF_BUTTONS == 2
#define BLE_ADVERTISEMENT_START_AND_LIGHTING_BUTTON DK_BTN2
#define BLE_ADVERTISEMENT_START_AND_LIGHTING_BUTTON_MASK DK_BTN2_MSK
#else
#define LIGHTING_BUTTON DK_BTN2
#define LIGHTING_BUTTON_MASK DK_BTN2_MSK
#define BLE_ADVERTISEMENT_START_BUTTON DK_BTN4
#define BLE_ADVERTISEMENT_START_BUTTON_MASK DK_BTN4_MSK
#endif

#define SYSTEM_STATE_LED DK_LED1
#define LIGHTING_STATE_LED DK_LED2
#if NUMBER_OF_LEDS == 4
#define FACTORY_RESET_SIGNAL_LED DK_LED3
#define FACTORY_RESET_SIGNAL_LED1 DK_LED4
#endif
```

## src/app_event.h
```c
/*
 * Copyright (c) 2021 Nordic Semiconductor ASA
 *
 * SPDX-License-Identifier: LicenseRef-Nordic-5-Clause
 */

#pragma once

#include <cstdint>

#include "event_types.h"

class LEDWidget;

enum class AppEventType : uint8_t {
	None = 0,
	Button,
	ButtonPushed,
	ButtonReleased,
	Timer,
	UpdateLedState,
	Lighting,
	IdentifyStart,
	IdentifyStop,
};

enum class FunctionEvent : uint8_t { NoneSelected = 0, SoftwareUpdate = 0, FactoryReset, AdvertisingStart };

struct AppEvent {
	union {
		struct {
			uint8_t PinNo;
			uint8_t Action;
		} ButtonEvent;
		struct {
			void *Context;
		} TimerEvent;
		struct {
			uint8_t Action;
			int32_t Actor;
		} LightingEvent;
		struct {
			LEDWidget *LedWidget;
		} UpdateLedStateEvent;
	};

	AppEventType Type{ AppEventType::None };
	EventHandler Handler;
};
```

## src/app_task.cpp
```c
/*
 * Copyright (c) 2021 Nordic Semiconductor ASA
 *
 * SPDX-License-Identifier: LicenseRef-Nordic-5-Clause
 */

#include "app_task.h"

#include "app/matter_init.h"
#include "app/task_executor.h"

#if defined(CONFIG_PWM)
#include "pwm/pwm_device.h"
#endif

#include "clusters/identify.h"

#include <app-common/zap-generated/attributes/Accessors.h>
#include <app/persistence/AttributePersistenceProviderInstance.h>
#include <app/persistence/DefaultAttributePersistenceProvider.h>
#include <app/persistence/DeferredAttributePersistenceProvider.h>
#include <app/server/Server.h>
#include <setup_payload/OnboardingCodesUtil.h>

#include <zephyr/logging/log.h>

LOG_MODULE_DECLARE(app, CONFIG_CHIP_APP_LOG_LEVEL);

using namespace ::chip;
using namespace ::chip::app;
using namespace ::chip::DeviceLayer;

namespace
{
constexpr EndpointId kLightEndpointId = 1;
constexpr uint8_t kDefaultMinLevel = 0;
constexpr uint8_t kDefaultMaxLevel = 254;

Nrf::Matter::IdentifyCluster sIdentifyCluster(kLightEndpointId, true, []() {
	Nrf::PostTask([] { Nrf::GetBoard().GetLED(Nrf::DeviceLeds::LED2).Set(false); });
#if defined(CONFIG_PWM)
	Nrf::PostTask([] { AppTask::Instance().GetPWMDevice().ApplyLevel(); });
#endif
});

#if defined(CONFIG_PWM)
const struct pwm_dt_spec sLightPwmDevice = PWM_DT_SPEC_GET(DT_ALIAS(pwm_led1));
#endif

/* Define a custom attribute persister which makes actual write of the CurrentLevel attribute value
 * to the non-volatile storage only when it has remained constant for 5 seconds. This is to reduce
 * the flash wearout when the attribute changes frequently as a result of MoveToLevel command.
 * DeferredAttribute object describes a deferred attribute, but also holds a buffer with a value to
 * be written, so it must live so long as the DeferredAttributePersistenceProvider object.
 */
DeferredAttribute gCurrentLevelPersister(ConcreteAttributePath(kLightEndpointId, Clusters::LevelControl::Id,
							       Clusters::LevelControl::Attributes::CurrentLevel::Id));

/* Deferred persistence will be auto-initialized as soon as the default persistence is initialized */
DefaultAttributePersistenceProvider gSimpleAttributePersistence;
DeferredAttributePersistenceProvider gDeferredAttributePersister(gSimpleAttributePersistence,
								 Span<DeferredAttribute>(&gCurrentLevelPersister, 1),
								 System::Clock::Milliseconds32(5000));

#define APPLICATION_BUTTON_MASK DK_BTN2_MSK
} /* namespace */

void AppTask::LightingActionEventHandler(const LightingEvent &event)
{
#if defined(CONFIG_PWM)
	Nrf::PWMDevice::Action_t action = Nrf::PWMDevice::INVALID_ACTION;
	int32_t actor = 0;
	if (event.Actor == LightingActor::Button) {
		action = Instance().mPWMDevice.IsTurnedOn() ? Nrf::PWMDevice::OFF_ACTION : Nrf::PWMDevice::ON_ACTION;
		actor = static_cast<int32_t>(event.Actor);
	}

	if (action == Nrf::PWMDevice::INVALID_ACTION || !Instance().mPWMDevice.InitiateAction(action, actor, NULL)) {
		LOG_INF("An action could not be initiated.");
	}
#else
	Nrf::GetBoard().GetLED(Nrf::DeviceLeds::LED2).Set(!Nrf::GetBoard().GetLED(Nrf::DeviceLeds::LED2).GetState());
#endif
}

void AppTask::ButtonEventHandler(Nrf::ButtonState state, Nrf::ButtonMask hasChanged)
{
	if ((APPLICATION_BUTTON_MASK & hasChanged) & state) {
		Nrf::PostTask([] {
			LightingEvent event;
			event.Actor = LightingActor::Button;
			LightingActionEventHandler(event);
		});
	}
}

#if defined(CONFIG_PWM)
void AppTask::ActionInitiated(Nrf::PWMDevice::Action_t action, int32_t actor)
{
	if (action == Nrf::PWMDevice::ON_ACTION) {
		LOG_INF("Turn On Action has been initiated");
	} else if (action == Nrf::PWMDevice::OFF_ACTION) {
		LOG_INF("Turn Off Action has been initiated");
	} else if (action == Nrf::PWMDevice::LEVEL_ACTION) {
		LOG_INF("Level Action has been initiated");
	}
}

void AppTask::ActionCompleted(Nrf::PWMDevice::Action_t action, int32_t actor)
{
	if (action == Nrf::PWMDevice::ON_ACTION) {
		LOG_INF("Turn On Action has been completed");
	} else if (action == Nrf::PWMDevice::OFF_ACTION) {
		LOG_INF("Turn Off Action has been completed");
	} else if (action == Nrf::PWMDevice::LEVEL_ACTION) {
		LOG_INF("Level Action has been completed");
	}

	if (actor == static_cast<int32_t>(LightingActor::Button)) {
		Instance().UpdateClusterState();
	}
}
#endif /* CONFIG_PWM */

void AppTask::UpdateClusterState()
{
	SystemLayer().ScheduleLambda([this] {
#if defined(CONFIG_PWM)
		/* write the new on/off value */
		Protocols::InteractionModel::Status status =
			Clusters::OnOff::Attributes::OnOff::Set(kLightEndpointId, mPWMDevice.IsTurnedOn());
#else
		Protocols::InteractionModel::Status status = Clusters::OnOff::Attributes::OnOff::Set(
			kLightEndpointId, Nrf::GetBoard().GetLED(Nrf::DeviceLeds::LED2).GetState());
#endif
		if (status != Protocols::InteractionModel::Status::Success) {
			LOG_ERR("Updating on/off cluster failed: %x", to_underlying(status));
		}

#if defined(CONFIG_PWM)
		/* write the current level */
		status = Clusters::LevelControl::Attributes::CurrentLevel::Set(kLightEndpointId, mPWMDevice.GetLevel());
#else
		/* write the current level */
		if (Nrf::GetBoard().GetLED(Nrf::DeviceLeds::LED2).GetState()) {
			status = Clusters::LevelControl::Attributes::CurrentLevel::Set(kLightEndpointId, 100);
		} else {
			status = Clusters::LevelControl::Attributes::CurrentLevel::Set(kLightEndpointId, 0);
		}
#endif

		if (status != Protocols::InteractionModel::Status::Success) {
			LOG_ERR("Updating level cluster failed: %x", to_underlying(status));
		}
	});
}

void AppTask::InitPWMDDevice()
{
#if defined(CONFIG_PWM)
	/* Initialize lighting device (PWM) */
	uint8_t minLightLevel = kDefaultMinLevel;
	Clusters::LevelControl::Attributes::MinLevel::Get(kLightEndpointId, &minLightLevel);

	uint8_t maxLightLevel = kDefaultMaxLevel;
	Clusters::LevelControl::Attributes::MaxLevel::Get(kLightEndpointId, &maxLightLevel);

	Clusters::LevelControl::Attributes::CurrentLevel::TypeInfo::Type currentLevel;
	Clusters::LevelControl::Attributes::CurrentLevel::Get(kLightEndpointId, currentLevel);

	int ret =
		mPWMDevice.Init(&sLightPwmDevice, minLightLevel, maxLightLevel, currentLevel.ValueOr(kDefaultMaxLevel));
	if (ret != 0) {
		LOG_ERR("Failed to initialize PWD device.");
	}

	mPWMDevice.SetCallbacks(ActionInitiated, ActionCompleted);
#endif
}

CHIP_ERROR AppTask::Init()
{
	/* Initialize Matter stack */
	ReturnErrorOnFailure(Nrf::Matter::PrepareServer(Nrf::Matter::InitData{ .mPostServerInitClbk = []() {
		app::SetAttributePersistenceProvider(&gDeferredAttributePersister);
		return gSimpleAttributePersistence.Init(Nrf::Matter::GetPersistentStorageDelegate());
	} }));

	if (!Nrf::GetBoard().Init(ButtonEventHandler)) {
		LOG_ERR("User interface initialization failed.");
		return CHIP_ERROR_INCORRECT_STATE;
	}

	/* Register Matter event handler that controls the connectivity status LED based on the captured Matter network
	 * state. */
	ReturnErrorOnFailure(Nrf::Matter::RegisterEventHandler(Nrf::Board::DefaultMatterEventHandler, 0));

	ReturnErrorOnFailure(sIdentifyCluster.Init());

	return Nrf::Matter::StartServer();
}

CHIP_ERROR AppTask::StartApp()
{
	ReturnErrorOnFailure(Init());

	while (true) {
		Nrf::DispatchNextTask();
	}

	return CHIP_NO_ERROR;
}
```

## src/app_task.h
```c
/*
 * Copyright (c) 2021 Nordic Semiconductor ASA
 *
 * SPDX-License-Identifier: LicenseRef-Nordic-5-Clause
 */

#pragma once

#include "board/board.h"
#include "pwm/pwm_device.h"

#include <platform/CHIPDeviceLayer.h>

struct k_timer;
struct Identify;

enum class LightingActor : uint8_t { Remote, Button };

struct LightingEvent {
	uint8_t Action;
	LightingActor Actor;
};

class AppTask {
public:
	static AppTask &Instance()
	{
		static AppTask sAppTask;
		return sAppTask;
	};

	CHIP_ERROR StartApp();

	void UpdateClusterState();
	void InitPWMDDevice();
	Nrf::PWMDevice &GetPWMDevice() { return mPWMDevice; }

private:
	CHIP_ERROR Init();

	static void LightingActionEventHandler(const LightingEvent &event);
	static void ButtonEventHandler(Nrf::ButtonState state, Nrf::ButtonMask hasChanged);

	static void ActionInitiated(Nrf::PWMDevice::Action_t action, int32_t actor);
	static void ActionCompleted(Nrf::PWMDevice::Action_t action, int32_t actor);

	Nrf::PWMDevice mPWMDevice;
};
```

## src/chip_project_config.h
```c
/*
 * Copyright (c) 2021 Nordic Semiconductor ASA
 *
 * SPDX-License-Identifier: LicenseRef-Nordic-5-Clause
 */

/**
 *    @file
 *          Example project configuration file for CHIP.
 *
 *          This is a place to put application or project-specific overrides
 *          to the default configuration values for general CHIP features.
 *
 */

#pragma once

// Reduce some flash space when the CONFIG_CHIP_MEMORY_PROFILING is selected
#ifdef CONFIG_CHIP_MEMORY_PROFILING
#define CHIP_CONFIG_LOG_MODULE_SecureChannel_PROGRESS 0
#define CHIP_CONFIG_LOG_MODULE_FabricProvisioning_PROGRESS 0
#define CHIP_CONFIG_LOG_MODULE_InteractionModel_PROGRESS 0
#define CHIP_CONFIG_LOG_MODULE_InteractionModel_DETAIL 0
#define CHIP_CONFIG_LOG_MODULE_DataManagement_PROGRESS 0
#endif
```

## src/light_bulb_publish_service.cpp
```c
/*
 * Copyright (c) 2021 Nordic Semiconductor ASA
 *
 * SPDX-License-Identifier: LicenseRef-Nordic-5-Clause
 */

#include "light_bulb_publish_service.h"

#include "app_task.h"

#include <logging/log.h>
#include <zephyr.h>

#include <inet/InetConfig.h>
#include <platform/CHIPDeviceLayer.h>
#include <transport/TransportMgr.h>
#include <transport/raw/UDP.h>

LOG_MODULE_DECLARE(app);

const char kPublishServicePayload[] = "chip-light-bulb";
const char kPublishDestAddr[] = "ff03::1";

using namespace ::chip;
using namespace ::chip::Inet;
using namespace ::chip::Transport;
using namespace ::chip::DeviceLayer;

void LightBulbPublishService::Init()
{
	mIsServiceStarted = false;

	/* Initialize timer */
	k_timer_init(&mPublishTimer, &PublishTimerHandler, nullptr);
	k_timer_user_data_set(&mPublishTimer, this);

	/* Initialize UDP endpoint */
	UdpListenParameters udpParams(chip::DeviceLayer::UDPEndPointManager());
	udpParams.SetListenPort(kServiceUDPPort);
	if (mUdp.Init(udpParams) != CHIP_NO_ERROR) {
		LOG_ERR("LightBulbPublishService initialization failed");
	}

	mMessageId = 0;
	IPAddress::FromString(kPublishDestAddr, mPublishDestAddr);
}

void LightBulbPublishService::Start(uint32_t aTimeoutInMs, uint32_t aIntervalInMs)
{
	if (!mIsServiceStarted) {
		if (aTimeoutInMs >= aIntervalInMs) {
			LOG_INF("Started Publish service");

			mPublishInterval = aIntervalInMs;
			/* Calculate number of publish iterations to do considering given timeout and interval values.
			 */
			mPublishIterations = aTimeoutInMs / aIntervalInMs;
			mIsServiceStarted = true;

			k_timer_start(&mPublishTimer, K_MSEC(aIntervalInMs), K_NO_WAIT);
		} else {
			LOG_ERR("Publish service cannot be started: service timeout is greater than interval");
		}
	} else {
		LOG_INF("Publish service is already running");
	}
}

void LightBulbPublishService::Stop()
{
	if (mIsServiceStarted) {
		LOG_INF("Stopped Publish service");

		k_timer_stop(&mPublishTimer);

		mIsServiceStarted = false;
		mMessageId = 0;
	} else {
		LOG_INF("Publish service is not running");
	}
}

void LightBulbPublishService::Publish()
{
	if (!chip::DeviceLayer::ConnectivityMgrImpl().IsThreadAttached()) {
		return;
	}

	const uint16_t payloadLength = sizeof(kPublishServicePayload);

	auto buffer = chip::System::PacketBufferHandle::NewWithData(kPublishServicePayload, payloadLength);
	if (!buffer.IsNull()) {
		if (mUdp.SendMessage(Transport::PeerAddress::UDP(mPublishDestAddr, kServiceUDPPort),
				     std::move(buffer)) == CHIP_NO_ERROR) {
			LOG_INF("LightBulbPublishService message sent successfully");
		} else {
			LOG_INF("LightBulbPublishService message sending failed");
		}
	}
}

void LightBulbPublishService::PublishTimerHandler(k_timer *aTimer)
{
	LightBulbPublishService *sLightBulbPublishService =
		reinterpret_cast<LightBulbPublishService *>(aTimer->user_data);
	if (sLightBulbPublishService->mPublishIterations > 0) {
		GetAppTask().PostEvent(AppEvent{ AppEvent::PublishLightBulbService });
		k_timer_start(&(sLightBulbPublishService->mPublishTimer),
			      K_MSEC(sLightBulbPublishService->mPublishInterval), K_NO_WAIT);
		sLightBulbPublishService->mPublishIterations--;
	} else {
		sLightBulbPublishService->Stop();
	}
}
```

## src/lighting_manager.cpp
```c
/*
 * Copyright (c) 2021 Nordic Semiconductor ASA
 *
 * SPDX-License-Identifier: LicenseRef-Nordic-5-Clause
 */

#include "lighting_manager.h"

#include <zephyr/drivers/pwm.h>
#include <zephyr/logging/log.h>
#include <zephyr/sys/util.h>
#include <zephyr/zephyr.h>

LOG_MODULE_DECLARE(app, CONFIG_MATTER_LOG_LEVEL);

LightingManager LightingManager::sLight;

int LightingManager::Init(const pwm_dt_spec *pwmDevice, uint8_t minLevel, uint8_t maxLevel)
{
	mState = State::On;
	mMinLevel = minLevel;
	mMaxLevel = maxLevel;
	mLevel = maxLevel;
	mPwmDevice = pwmDevice;

	if (!device_is_ready(mPwmDevice->dev)) {
		LOG_ERR("PWM device %s is not ready", mPwmDevice->dev->name);
		return -ENODEV;
	}

	Set(false);
	return 0;
}

void LightingManager::SetCallbacks(LightingCallback_fn aActionInitiated_CB, LightingCallback_fn aActionCompleted_CB)
{
	mActionInitiated_CB = aActionInitiated_CB;
	mActionCompleted_CB = aActionCompleted_CB;
}

bool LightingManager::InitiateAction(Action aAction, uint8_t value, bool chipInitiated)
{
	bool actionInitiated = false;
	State newState;

	/* Initiate On/Off Action only when the previous one is complete. */
	if (mState == State::Off && aAction == Action::On) {
		actionInitiated = true;
		newState = State::On;
	} else if (mState == State::On && aAction == Action::Off) {
		actionInitiated = true;
		newState = State::Off;
	} else if (aAction == Action::Level && value != mLevel) {
		actionInitiated = true;
		newState = (value == 0) ? State::Off : State::On;
	}

	if (actionInitiated) {
		if (mActionInitiated_CB) {
			mActionInitiated_CB(aAction);
		}

		if (aAction == Action::On || aAction == Action::Off) {
			Set(newState == State::On);
		} else if (aAction == Action::Level) {
			SetLevel(value);
		}

		mChipInitiatedAction = chipInitiated;

		if (mActionCompleted_CB) {
			mActionCompleted_CB(aAction);
		}
	}

	return actionInitiated;
}

void LightingManager::SetLevel(uint8_t aLevel)
{
	LOG_INF("Setting brightness level to %u", aLevel);
	mLevel = aLevel;
	UpdateLight();
}

void LightingManager::Set(bool aOn)
{
	mState = aOn ? State::On : State::Off;
	UpdateLight();
}

void LightingManager::UpdateLight()
{
	const uint8_t maxEffectiveLevel = mMaxLevel - mMinLevel;
	const uint8_t effectiveLevel = mState == State::On ? MIN(mLevel - mMinLevel, maxEffectiveLevel) : 0;

	pwm_set_pulse_dt(mPwmDevice, static_cast<uint32_t>(static_cast<const uint64_t>(mPwmDevice->period) *
							   effectiveLevel / maxEffectiveLevel));
}
```
